# RS14100 register map
File version: 1.0
CPU: CM4 r0p1, little endian, MPU, FPU, 4 interrupt priority bits
Registers are 32-bit, read-write, reset 0x0 unless marked. A register's access mark holds for its fields unless they carry their own. Offsets are from the block's base; [hi:lo] are bit positions; {n}, {i} and the like mark numbered series; 'fields as' and 'values as' point back to an identical list.

## QSPI — The queued serial peripheral interface module provides a serial peripheral interface with queued transfer capability
Base 0x12000000
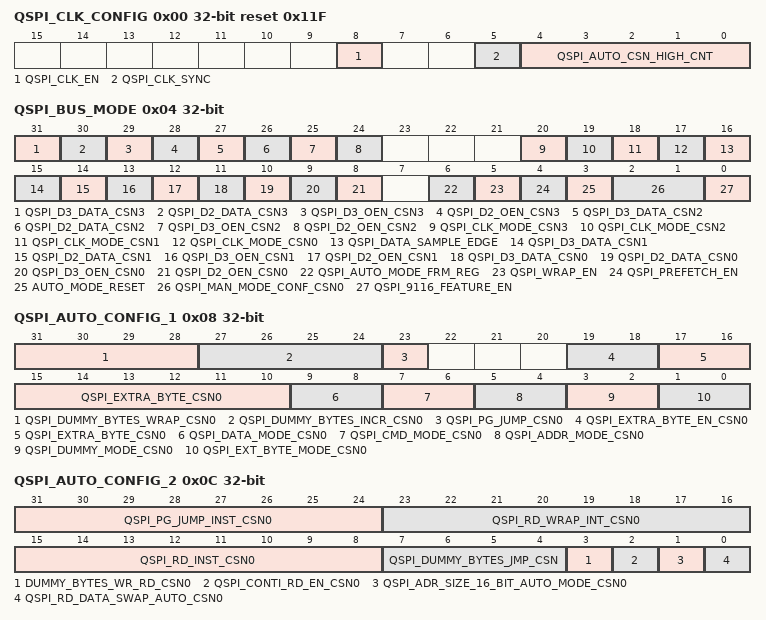
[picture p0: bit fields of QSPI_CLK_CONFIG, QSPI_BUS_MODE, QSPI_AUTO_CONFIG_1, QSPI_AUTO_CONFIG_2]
0x00 QSPI_CLK_CONFIG reset 0x11F — QSPI Clock Configuration Register
  [8] QSPI_CLK_EN — QSPI clock enable
    0=Disable (Dynamic clock gating is enabled in side QSPI controller); 1=Enable (Full time clock is enabled for QSPI controller.)
  [5] QSPI_CLK_SYNC — If the clock frequency to FLASH(spi_clk) and QSPI(hclk) controller is same, this bit can be set to one to by-pass the syncros results in time consumption
    0=Disable (Sync logic is enabled); 1=Enable (Sync (synchros) logic is bypassed)
  [4:0] QSPI_AUTO_CSN_HIGH_CNT — Minimum SOC clock cycles, during which QSPI auto csn should be high between consecutive CSN assertions
0x04 QSPI_BUS_MODE
  [31] QSPI_D3_DATA_CSN3 — Value of SPI_IO3 in case of dual/single mode for chip select3 csn3
  [30] QSPI_D2_DATA_CSN3 — Value of SPI_IO2 in case of dual/single mode for chip select3 csn3
  [29] QSPI_D3_OEN_CSN3 — Direction Control for SPI_IO3 in case of dual/single mode for chip select3 csn3
  [28] QSPI_D2_OEN_CSN3 — Direction Control for SPI_IO2 in case of dual/single mode for chip select3 csn3
  [27] QSPI_D3_DATA_CSN2 — Value of SPI_IO3 in case of dual/single mode for chip select2 csn2
  [26] QSPI_D2_DATA_CSN2 — Value of SPI_IO2 in case of dual/single mode for chip select2 csn2
  [25] QSPI_D3_OEN_CSN2 — Direction Control for SPI_IO3 in case of dual/single mode for chip select2 csn2
  [24] QSPI_D2_OEN_CSN2 — Direction Control for SPI_IO2 in case of dual/single mode for chip select2 csn2
  [20] QSPI_CLK_MODE_CSN3 — QSPI Clock Mode
    0=Mode 0, QSPI_CLK is low when QSPI_CS is high for chip select3 csn3; 1=Mode 3, QSPI_CLK is high when QSPI_CS is high for chip select3 csn3
  [19] QSPI_CLK_MODE_CSN2 — QSPI Clock Mode
    0=Mode 0 QSPI_CLK is low when QSPI_CS is high for chip select2 csn2; 1=Mode 3 QSPI_CLK is high when QSPI_CS is high for chip select2 csn2
  [18] QSPI_CLK_MODE_CSN1 — QSPI Clock Mode
    0=Mode 0, QSPI_CLK is low when QSPI_CS is high for chip select1 csn1; 1=Mode 3, QSPI_CLK is high when QSPI_CS is high for chip select1 csn1
  [17] QSPI_CLK_MODE_CSN0 — QSPI Clock Mode
    0=Mode 0, QSPI_CLK is low when QSPI_CS is high for chip select0 csn0; 1=Mode 3, QSPI_CLK is high when QSPI_CS is high for chip select0 csn0
  [16] QSPI_DATA_SAMPLE_EDGE — Samples MISO data on clock edges
    0=Disable (Pos edge of loop back spi_pad_clk); 1=Enable (Neg edge of loop back spi_pad_clk)
  [15] QSPI_D3_DATA_CSN1 — Value of SPI_IO3 in case of dual/single mode for chip select1 csn1
  [14] QSPI_D2_DATA_CSN1 — Direction Control for SPI_IO3 in case of dual/single mode for chip select1 csn1
  [13] QSPI_D3_OEN_CSN1 — Direction Control for SPI_IO3 in case of dual/single mode for chip select1 csn1
  [12] QSPI_D2_OEN_CSN1 — Direction Control for SPI_IO2 in case of dual/single mode for chip select1 csn1
  [11] QSPI_D3_DATA_CSN0 — Value of SPI_IO3 in case of dual/single mode for chip select0 csn0. It is used both in Auto and Manual Mode
  [10] QSPI_D2_DATA_CSN0 — Value of SPI_IO2 in case of dual/single mode for chip select0 csn0. It is used both in Auto and Manual Mode.
  [9] QSPI_D3_OEN_CSN0 — Direction Control for SPI_IO3 in case of dual/single mode for chip select0 csn0. It is used both in Auto and Manual Mode.
  [8] QSPI_D2_OEN_CSN0 — Direction Control for SPI_IO2 in case of dual/single mode for chip select0 csn0. It is used both in Auto and Manual Mode
  [6] QSPI_AUTO_MODE_FRM_REG — QSPI Mode of Operation
    0=Disable (Manual Mode is selected); 1=Enable (Auto Mode is selected.)
  [5] QSPI_WRAP_EN — Model wrap is considered with this bit and uses wrap instruction to read from FLASH
    0=Disable (Wrap mode is disabled (AHB WRAP can be used).); 1=Enable (Wrap mode is enabled)
  [4] QSPI_PREFETCH_EN — Pre-fetch of data from the model which is connected to QSPI, automatically with out reading on AHB and is supplied to AHB, when address is matched with AHB read transaction address
    0=Disable (Pre-fetch mode is disabled.); 1=Enable (Pre-fetch mode is enabled)
  [3] AUTO_MODE_RESET — QSPI Auto controller reset. This is not a Self clearing bit
    0=Disable (Auto mode is active); 1=Enable (Auto mode is inactive)
  [2:1] QSPI_MAN_MODE_CONF_CSN0 — Configures the QSPI flash for Single/Dual/Quad mode operation in manual mode
    0=Single Mode; 1=Dual Mode; 2=Quad Mode; 3=none
  [0] QSPI_9116_FEATURE_EN — 9115 specific features are enabled with this enable
0x08 QSPI_AUTO_CONFIG_1 — QSPI Auto Controller Configuration 1 Register
  [31:28] QSPI_DUMMY_BYTES_WRAP_CSN0 — Specifies the number of dummy bytes 0 to 7 for the selected SPI mode in case of wrap instruction
  [27:24] QSPI_DUMMY_BYTES_INCR_CSN0 — Specifies the number of dummy bytes 0 to 7 for the selected SPI mode
  [23] QSPI_PG_JUMP_CSN0
    0=NOT_INDEX_JUMP_INSTRUCTION (Do not use Index jump instruction); 1=INDEX_JUMP_INSTRUCTION (Use Index jump instruction specified by QSPI_PG_JUMP_INST)
  [19:18] QSPI_EXTRA_BYTE_EN_CSN0 — Value of the extra byte to be transmitted, if the extra byte mode is enabled
    0=Do not transmit extra byte; 1=Transmit Extra byte after address phase; 2=Transmit only first nibble of the byte and maintain Hi-Z on the IO bus for next nibble; 3=none
  [17:10] QSPI_EXTRA_BYTE_CSN0 — Value of the extra byte to be transmitted, if the extra byte mode is enabled
  [9:8] QSPI_DATA_MODE_CSN0 — Mode of operation of QSPI in DATA phase
    0=SPI; 1=Dual SPI; 2=Quad SPI; 3=none
  [7:6] QSPI_CMD_MODE_CSN0 — Mode of operation of QSPI in instruction phase
    0=SPI; 1=Dual SPI; 2=Quad SPI; 3=none
  [5:4] QSPI_ADDR_MODE_CSN0 — Mode of operation of QSPI in instruction phase
    0=SPI; 1=Dual SPI; 2=Quad SPI; 3=none
  [3:2] QSPI_DUMMY_MODE_CSN0 — Mode of operation of QSPI in instruction phase
    0=SPI; 1=Dual SPI; 2=Quad SPI; 3=none
  [1:0] QSPI_EXT_BYTE_MODE_CSN0 — Mode of operation of QSPI in the extra byte phase
    0=SPI; 1=Dual SPI; 2=Quad SPI; 3=none
0x0C QSPI_AUTO_CONFIG_2 — QSPI Auto Controller Configuration 2 Register
  [31:24] QSPI_PG_JUMP_INST_CSN0 — Read instruction to be used, when Page jump is to be used
  [23:16] QSPI_RD_WRAP_INT_CSN0 — Read instruction to be used, when wrap mode is supported by QSPI flash
  [15:8] QSPI_RD_INST_CSN0 — Read instruction to be used for the selected SPI modes and when wrap
  [7:4] QSPI_DUMMY_BYTES_JMP_CSN — Dummy cycles to be selected in case of JUMP
  [3] DUMMY_BYTES_WR_RD_CSN0 — Dummy bytes to the model to be read or to be write
    0=Disable (Dummy bytes will be read); 1=Enable (Dummy bytes to be write.)
  [2] QSPI_CONTI_RD_EN_CSN0
    0=Disable (Continuous read disabled.); 1=Enable (Continuous read enabled.)
  [1] QSPI_ADR_SIZE_16_BIT_AUTO_MODE_CSN0
    0=Disable (24 bit address is sent to model); 1=Enable (16 Bit address is sent to model)
  [0] QSPI_RD_DATA_SWAP_AUTO_CSN0
    0=Disable (Do not swap the read data in auto mode); 1=Enable (Swap the auto read data in auto mode)
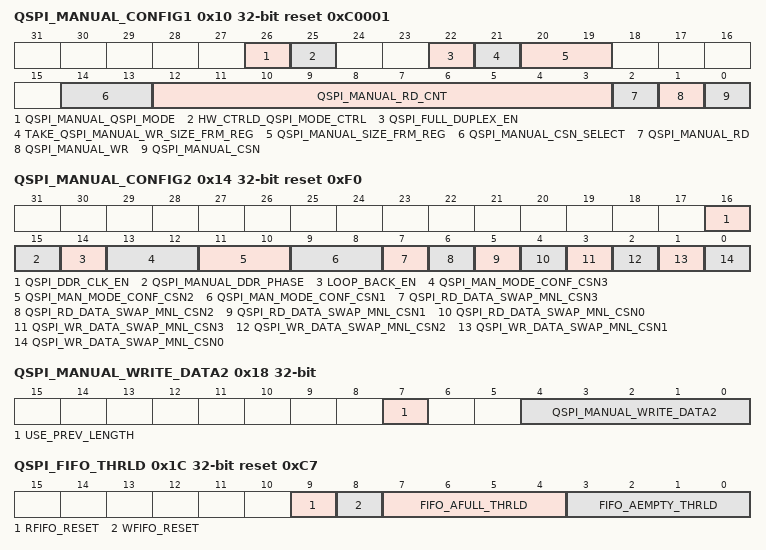
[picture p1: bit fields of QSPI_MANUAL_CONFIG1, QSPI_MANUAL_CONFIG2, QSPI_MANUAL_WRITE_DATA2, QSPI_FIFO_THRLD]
0x10 QSPI_MANUAL_CONFIG1 reset 0xC0001 — QSPI Manual Configuration 1 Register
  [26] QSPI_MANUAL_QSPI_MODE — Internally the priority is given to manual mode
    0=Disable (SPI mode); 1=Enable (Host SPI mode.)
  [25] HW_CTRLD_QSPI_MODE_CTRL — Hardware controlled qspi mode in between AUTO and manual
    0=Disable (Hardware control is disabled); 1=Enable (Hardware control is enabled.)
  [22] QSPI_FULL_DUPLEX_EN — Full duplex mode enable.
    0=Disable (Full duplex mode disabled.); 1=Enable (Full duplex mode enabled)
  [21] TAKE_QSPI_MANUAL_WR_SIZE_FRM_REG
    0=Disable (No action. Takes write size from fifo); 1=Enable (Take write size from Manual config register1)
  [20:19] QSPI_MANUAL_SIZE_FRM_REG — Manual reads and manual writes follow this size
    0=1BYTE_MODE (1 Byte 8 bit mode); 1=2BYTE_MODE (2 Bytes 16 bit mode); 2=3BYTE_MODE (3 Bytes 24 bit mode); 3=4BYTE_MODE (4 Bytes 32 bit mode)
  [14:13] QSPI_MANUAL_CSN_SELECT — Indicates which CSn is valid
  [12:3] QSPI_MANUAL_RD_CNT — Indicates total number of bytes to be read along with 31:27 bits of this register. Maximum length supported is 32k bytes
  [2] QSPI_MANUAL_RD — Read enable for manual mode when CS is low
  [1] QSPI_MANUAL_WR — Write enable for manual mode when CS is low
  [0] QSPI_MANUAL_CSN — SPI CS in manual mode
0x14 QSPI_MANUAL_CONFIG2 reset 0xF0 (reset mask 0xFFF) — QSPI Manual Configuration 2 Register
  [16] QSPI_DDR_CLK_EN — DDR operations can be performed even in manual mode
    0=Use SDR mode clk; 1=Use DDR mode clk
  [15] QSPI_MANUAL_DDR_PHASE — DDR operations can be performed even in manual mode
  [14] LOOP_BACK_EN — Internal loop back test mode.
  [13:12] QSPI_MAN_MODE_CONF_CSN3 — Configures the QSPI flash for Single or Dual or Quad mode operation in manual mode for chip select3 csn3
    0=Single; 1=Dual; 2=Quad; 3=none
  [11:10] QSPI_MAN_MODE_CONF_CSN2 — Configures the QSPI flash for Single or Dual or Quad mode operation in manual mode for chip select2 csn2
    0=Single; 1=Dual; 2=Quad; 3=none
  [9:8] QSPI_MAN_MODE_CONF_CSN1 — Configures the QSPI flash for Single/Dual/Quad mode operation in manual mode for chip select1 csn1
    0=Single; 1=Dual; 2=Quad; 3=none
  [7] QSPI_RD_DATA_SWAP_MNL_CSN3 — Swap the read data inside the QSPIcontroller itself
    0=Disable (Manual read data swap is disabled for csn3); 1=Enable (Manual read data swap is enabled for csn3)
  [6] QSPI_RD_DATA_SWAP_MNL_CSN2 — Swap the read data inside the QSPIcontroller it-self
    0=Disable (Manual read data swap is disabled for csn2); 1=Enable (Manual read data swap is enabled for csn2)
  [5] QSPI_RD_DATA_SWAP_MNL_CSN1 — Swap the read data inside the QSPIcontroller itself.
    0=Disable (Manual read data swap is disabled for csn1); 1=Enable (Manual read data swap is enabled for csn1)
  [4] QSPI_RD_DATA_SWAP_MNL_CSN0 — Swap the read data inside the QSPIcontroller it self.
    0=Disable (Manual read data swap is disabled for csn0.); 1=Enable (Manual read data swap is enabled for csn0.)
  [3] QSPI_WR_DATA_SWAP_MNL_CSN3 — Swap the write data inside the QSPI controller itself.
    0=Disable (Manual write data swap is disabled for csn3.); 1=Enable (Manual write data swap is enabled for csn3.)
  [2] QSPI_WR_DATA_SWAP_MNL_CSN2 — Swap the write data inside the QSPI controller itself.
    0=Disable (Manual write data swap is disabled for csn2.); 1=Enable (Manual write data swap is enabled for csn2.)
  [1] QSPI_WR_DATA_SWAP_MNL_CSN1 — Swap the write data inside the QSPI controller it-self.
    0=Disable (Manual write data swap is disabled for csn1.); 1=Enable (Manual write data swap is enabled for csn1.)
  [0] QSPI_WR_DATA_SWAP_MNL_CSN0 — Swap the write data inside the QSPI controller it-self
    0=Disable (Manual write data swap is disabled for csn0.); 1=Enable (Manual write data swap is enabled for csn0.)
0x18 QSPI_MANUAL_WRITE_DATA2
  [7] USE_PREV_LENGTH — Use previous length.
    0=Disable (No action); 1=Enable (Uses previously programmed length in 4:0 of this register for next writes)
  [4:0] QSPI_MANUAL_WRITE_DATA2 — Number of bits to be written in write mode
0x1C QSPI_FIFO_THRLD reset 0xC7 (reset mask 0x1FF) — QSPI FIFO Threshold Register
  [9] RFIFO_RESET — Read fifo reset
  [8] WFIFO_RESET — Write fifo reset
  [7:4] FIFO_AFULL_THRLD — FIFO almost full threshold
  [3:0] FIFO_AEMPTY_THRLD — FIFO almost empty threshold
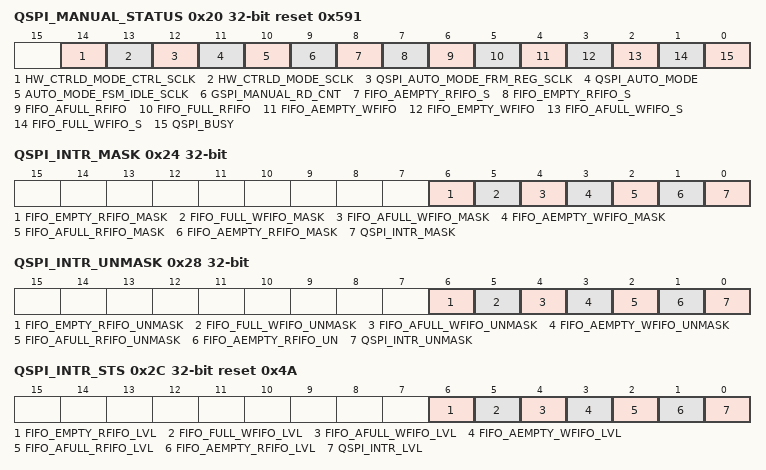
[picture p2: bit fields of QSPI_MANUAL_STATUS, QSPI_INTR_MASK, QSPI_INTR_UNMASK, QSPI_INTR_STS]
0x20 QSPI_MANUAL_STATUS ro reset 0x591
  [14] HW_CTRLD_MODE_CTRL_SCLK — HW_CTRLD_MODE status
    0=Disable (HW_CTRL_MODE is disabled.); 1=Enable (HW_CTRL_MODE is enabled)
  [13] HW_CTRLD_MODE_SCLK — QSPI mode status in HW_CTRLD_MODE
    0=Disable (QSPI controller is in MANUAL mode.); 1=Enable (QSPI controller is working in AUTO MODE.)
  [12] QSPI_AUTO_MODE_FRM_REG_SCLK — QSPI auto mode status. Valid only when HW_CTRLD_QSPI_MODE_CTRL is zero.
    0=Disable (QSPI controller is hot coded to manual mode operations.); 1=Enable (QSPI controller is hot coded to AUTO mode operations)
  [11] QSPI_AUTO_MODE — QSPI controller status.
    0=Disable (QSPI controller is in manual mode.); 1=Enable (QSPI controller is in auto mode.)
  [10] AUTO_MODE_FSM_IDLE_SCLK — Auto mode idle signal to track auto controller is busy or idle.
    0=Disable (Auto mode is busy); 1=Enable (Auto mode is idle)
  [9] GSPI_MANUAL_RD_CNT — This is a result of 10 bits ORing counter
    0=Disable (No read transactions are in pending); 1=Enable (Read transactions are in pending ( to be done))
  [8] FIFO_AEMPTY_RFIFO_S — Status indication for Rfifo in manual mode
  [7] FIFO_EMPTY_RFIFO_S — Status indication for Rfifo in manual mode
  [6] FIFO_AFULL_RFIFO — Status indication for Rfifo in manual mode
  [5] FIFO_FULL_RFIFO — Status indication for Rfifo in manual mode
  [4] FIFO_AEMPTY_WFIFO — Status indication for Wfifo in manual mode
  [3] FIFO_EMPTY_WFIFO — Status indication for Wfifo in manual mode
  [2] FIFO_AFULL_WFIFO_S — Status indication for Wfifo in manual mode
  [1] FIFO_FULL_WFIFO_S — Status indication for Wfifo in manual mode
  [0] QSPI_BUSY — State of Manual mode.
    0=Disable (QSPI controller is IDLE in Manual mode.); 1=Enable (A read, write or dummy cycle operation is in process in manual mode.)
0x24 QSPI_INTR_MASK (reset mask 0x6F) — QSPI Interrupt Mask Register
  [6] FIFO_EMPTY_RFIFO_MASK
    0=Disable (Do not touch); 1=Enable (Read fifo is empty intr mask)
  [5] FIFO_FULL_WFIFO_MASK
    0=Disable (Do not touch); 1=Enable (write fifo full intr mask)
  [4] FIFO_AFULL_WFIFO_MASK
    0=Disable (Do not touch); 1=Enable (Write fifo almost full intr mask)
  [3] FIFO_AEMPTY_WFIFO_MASK
    0=Disable (Do not touch); 1=Enable (write fifo almost empty intr mask.)
  [2] FIFO_AFULL_RFIFO_MASK
    0=Disable (Do not touch); 1=Enable (read fifo almost full intr mask)
  [1] FIFO_AEMPTY_RFIFO_MASK
    0=Disable (Do not touch); 1=Enable (Read fifo almost empty intr mask.)
  [0] QSPI_INTR_MASK — Interrupt Status bit
    0=Disable (Do not touch); 1=Enable (mask the qspi intr)
0x28 QSPI_INTR_UNMASK — QSPI Interrupt Unmask Register
  [6] FIFO_EMPTY_RFIFO_UNMASK
    0=Disable (Do not touch); 1=Enable (Read fifo is empty intr unmask)
  [5] FIFO_FULL_WFIFO_UNMASK
    0=Disable (Do not touch); 1=Enable (write fifo full intr unmask)
  [4] FIFO_AFULL_WFIFO_UNMASK
    0=Disable (Do not touch); 1=Enable (Write fifo almost full intr unmask.)
  [3] FIFO_AEMPTY_WFIFO_UNMASK
    0=Disable (Do not touch); 1=Enable (write fifo almost empty intr unmask)
  [2] FIFO_AFULL_RFIFO_UNMASK
    0=Disable (Do not touch); 1=Enable (read fifo almost full intr unmask.)
  [1] FIFO_AEMPTY_RFIFO_UN
    0=Disable (Do not touch); 1=Enable (Read fifo almost empty intr unmask)
  [0] QSPI_INTR_UNMASK — Interrupt Status bit
    0=Disable (Do not touch); 1=Enable (unmask the qspi intr)
0x2C QSPI_INTR_STS ro reset 0x4A — QSPI Interrupt Status Register
  [6] FIFO_EMPTY_RFIFO_LVL
    0=Disable (Read FIFO is not empty); 1=Enable (Read FIFO is empty)
  [5] FIFO_FULL_WFIFO_LVL
    0=Disable (Write fifo not got full); 1=Enable (write fifo got full.)
  [4] FIFO_AFULL_WFIFO_LVL
    0=Disable (write FIFO not reached almost full threshold); 1=Enable (Write FIFO reached almost full threshold)
  [3] FIFO_AEMPTY_WFIFO_LVL
    0=Disable (write FIFO not reached almost full threshold.); 1=Enable (write FIFO reached almost empty threshold.)
  [2] FIFO_AFULL_RFIFO_LVL
    0=Disable (read FIFO do not reached almost full threshold); 1=Enable (read FIFO reached almost full threshold)
  [1] FIFO_AEMPTY_RFIFO_LVL
    0=Disable (Read fifo does not reached almost empty threshold); 1=Enable (Read fifo reached almost empty threshold)
  [0] QSPI_INTR_LVL — Interrupt Status bit
    0=Disable (no interrupt); 1=Enable (qspi raised a interrupt)
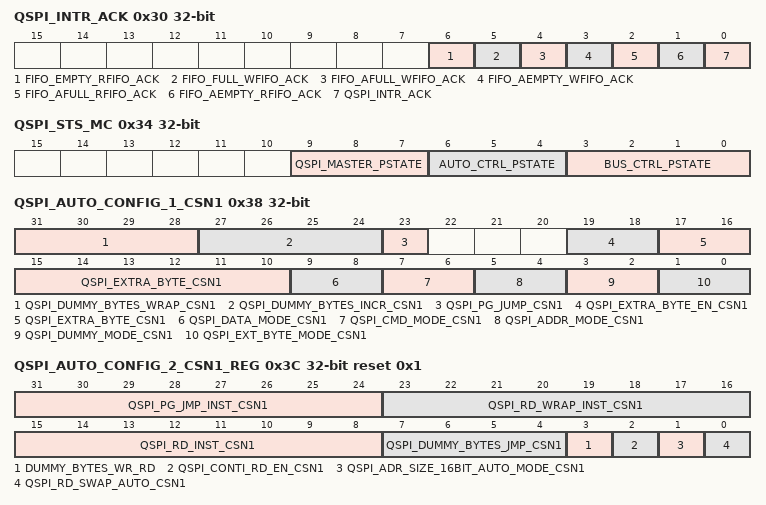
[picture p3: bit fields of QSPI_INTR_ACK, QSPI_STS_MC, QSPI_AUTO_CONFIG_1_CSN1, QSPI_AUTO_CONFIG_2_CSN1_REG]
0x30 QSPI_INTR_ACK wo — QSPI Interrupt Acknowledge Register
  [6] FIFO_EMPTY_RFIFO_ACK
    values as QSPI_INTR_UNMASK.FIFO_EMPTY_RFIFO_UNMASK
  [5] FIFO_FULL_WFIFO_ACK
    values as QSPI_INTR_UNMASK.FIFO_FULL_WFIFO_UNMASK
  [4] FIFO_AFULL_WFIFO_ACK
    values as QSPI_INTR_UNMASK.FIFO_AFULL_WFIFO_UNMASK
  [3] FIFO_AEMPTY_WFIFO_ACK
    0=Disable (Do not touch); 1=Enable (write fifo almost empty intr unmask.)
  [2] FIFO_AFULL_RFIFO_ACK
    values as QSPI_INTR_UNMASK.FIFO_AFULL_RFIFO_UNMASK
  [1] FIFO_AEMPTY_RFIFO_ACK
    values as QSPI_INTR_UNMASK.FIFO_AEMPTY_RFIFO_UN
  [0] QSPI_INTR_ACK — Interrupt Status bit
    0=Disable (Do not touch); 1=Enable (unmask the qspi intr.)
0x34 QSPI_STS_MC ro (reset mask 0x6FF) — QSPI State Machine Monitor Register
  [9:7] QSPI_MASTER_PSTATE — Qspi master present state
  [6:4] AUTO_CTRL_PSTATE — Auto controller present state
  [3:0] BUS_CTRL_PSTATE — Bus controller present state
0x38 QSPI_AUTO_CONFIG_1_CSN1 (reset mask 0x87FFFF) — QSPI Auto Controller Configuration 1 CSN1 Register
  [31:28] QSPI_DUMMY_BYTES_WRAP_CSN1 ro — Specifies the number of dummy bytes 0 to 7 for the selected SPI mode in case of wrap instruction.
  [27:24] QSPI_DUMMY_BYTES_INCR_CSN1 ro — Specifies the number of dummy bytes 0 to 7 for the selected SPI mode.
  [23] QSPI_PG_JUMP_CSN1 wo
    0=Disable (Do not use Index jump instruction.); 1=Enable (Use Index jump instruction specified by QSPI_PG_JUMP_INST)
  [19:18] QSPI_EXTRA_BYTE_EN_CSN1 — Mode of operation of QSPI in DATA phase.
    values as QSPI_AUTO_CONFIG_1.QSPI_EXTRA_BYTE_EN_CSN0
  [17:10] QSPI_EXTRA_BYTE_CSN1 ro — Value of the extra byte to be transmitted, if the extra byte mode is enabled.
  [9:8] QSPI_DATA_MODE_CSN1 — Mode of operation of QSPI in DATA phase.
    0=SPI; 1=Dual SPI; 2=Quad SPI; 3=none
  [7:6] QSPI_CMD_MODE_CSN1 — Mode of operation of QSPI in instruction phase.
    0=SPI; 1=Dual SPI; 2=Quad SPI; 3=none
  [5:4] QSPI_ADDR_MODE_CSN1 — Mode of operation of QSPI in instruction phase.
    0=SPI; 1=Dual SPI; 2=Quad SPI; 3=none
  [3:2] QSPI_DUMMY_MODE_CSN1 — Mode of operation of QSPI in instruction phase
    0=SPI; 1=Dual SPI; 2=Quad SPI; 3=none
  [1:0] QSPI_EXT_BYTE_MODE_CSN1 — Mode of operation of QSPI in instruction phase.
    0=SPI; 1=Dual SPI; 2=Quad SPI; 3=none
0x3C QSPI_AUTO_CONFIG_2_CSN1_REG reset 0x1 — QSPI Auto Controller Configuration 2 CSN1 Register
  [31:24] QSPI_PG_JMP_INST_CSN1 — Read instruction to be used, when Page jump is to be used.
  [23:16] QSPI_RD_WRAP_INST_CSN1 — Read instruction to be used for the selected SPI modes and when wrap is not needed or supported
  [15:8] QSPI_RD_INST_CSN1 — Read instruction to be used for the selected SPI modes and when wrap is not needed or supported
  [7:4] QSPI_DUMMY_BYTES_JMP_CSN1 — Dummy cycles to be selected in case of JUMP
  [3] DUMMY_BYTES_WR_RD — Dummy bytes to the model to be read or to be write.
    0=READ (Dummy bytes will be read.); 1=WRITE (Dummy bytes to be write.)
  [2] QSPI_CONTI_RD_EN_CSN1 — Continuous read enable bit.
    0=disable (Continuous read disabled); 1=enable (Continuous read enabled)
  [1] QSPI_ADR_SIZE_16BIT_AUTO_MODE_CSN1
    0=24BIT_ADDRESS (24 bit address is sent to model); 1=16BIT_ADDRESS (16 Bit address is sent to model.)
  [0] QSPI_RD_SWAP_AUTO_CSN1 — Swap the read data from the flash in byte order for chip select1 csn1 in auto mode.
    0=Swap is disabled; 1=Swap is enabled
{0x40+4i} QSPI_MANUAL_RDWR_FIFO[{i}] (i=0..15) — QSPI FIFOs
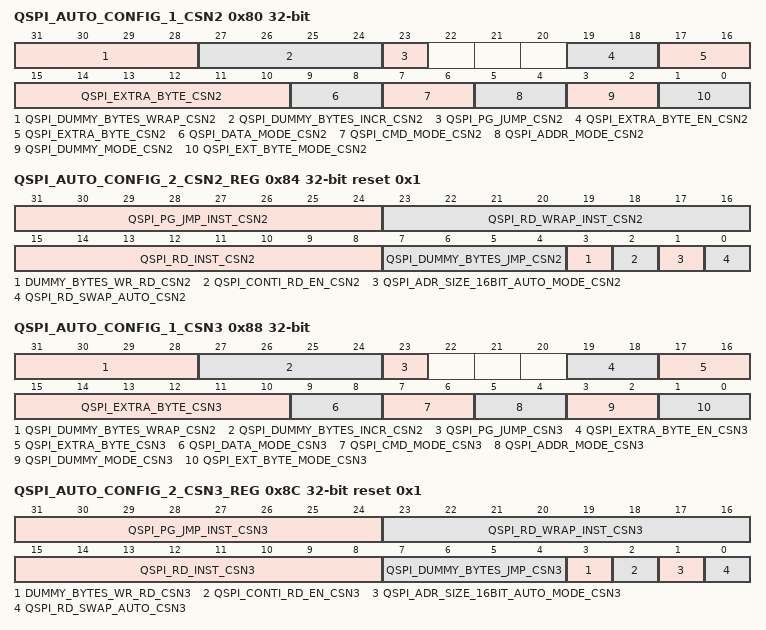
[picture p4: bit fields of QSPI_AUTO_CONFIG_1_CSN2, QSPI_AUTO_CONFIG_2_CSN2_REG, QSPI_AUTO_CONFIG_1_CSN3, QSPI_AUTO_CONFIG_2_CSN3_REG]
0x80 QSPI_AUTO_CONFIG_1_CSN2 (reset mask 0x87FFFF) — QSPI Auto Controller Configuration 1 CSN2 Register
  [31:28] QSPI_DUMMY_BYTES_WRAP_CSN2 ro — Specifies the number of dummy bytes 0 to 7 for the selected SPI mode in case of wrap instruction.
  [27:24] QSPI_DUMMY_BYTES_INCR_CSN2 ro — Specifies the number of dummy bytes 0 to 7 for the selected SPI mode.
  [23] QSPI_PG_JUMP_CSN2 wo
    values as QSPI_AUTO_CONFIG_1_CSN1.QSPI_PG_JUMP_CSN1
  [19:18] QSPI_EXTRA_BYTE_EN_CSN2 — Mode of operation of QSPI in DATA phase.
    values as QSPI_AUTO_CONFIG_1.QSPI_EXTRA_BYTE_EN_CSN0
  [17:10] QSPI_EXTRA_BYTE_CSN2 ro — Value of the extra byte to be transmitted, if the extra byte mode is enabled.
  [9:8] QSPI_DATA_MODE_CSN2 — Mode of operation of QSPI in DATA phase.
    0=SPI; 1=Dual SPI; 2=Quad SPI; 3=none
  [7:6] QSPI_CMD_MODE_CSN2 — Mode of operation of QSPI in instruction phase.
    0=SPI; 1=Dual SPI; 2=Quad SPI; 3=none
  [5:4] QSPI_ADDR_MODE_CSN2 — Mode of operation of QSPI in instruction phase.
    0=SPI; 1=Dual SPI; 2=Quad SPI; 3=none
  [3:2] QSPI_DUMMY_MODE_CSN2 — Mode of operation of QSPI in instruction phase
    0=SPI; 1=Dual SPI; 2=Quad SPI; 3=none
  [1:0] QSPI_EXT_BYTE_MODE_CSN2 — Mode of operation of QSPI in instruction phase.
    0=SPI; 1=Dual SPI; 2=Quad SPI; 3=none
0x84 QSPI_AUTO_CONFIG_2_CSN2_REG reset 0x1 — QSPI Auto Controller Configuration 2 CSN2 Register
  [31:24] QSPI_PG_JMP_INST_CSN2 — Read instruction to be used, when Page jump is to be used.
  [23:16] QSPI_RD_WRAP_INST_CSN2 — Read instruction to be used for the selected SPI modes and when wrap is not needed or supported
  [15:8] QSPI_RD_INST_CSN2 — Read instruction to be used for the selected SPI modes and when wrap is not needed or supported
  [7:4] QSPI_DUMMY_BYTES_JMP_CSN2 — Dummy cycles to be selected in case of JUMP
  [3] DUMMY_BYTES_WR_RD_CSN2 — Dummy bytes to the model to be read or to be write.
    0=Dummy bytes will be read; 1=Dummy bytes to be write
  [2] QSPI_CONTI_RD_EN_CSN2 — Continuous read enable bit.
    0=Continuous read disabled; 1=Continuous read enabled
  [1] QSPI_ADR_SIZE_16BIT_AUTO_MODE_CSN2
    0=24 bit address is sent to model; 1=16 Bit address is sent to model
  [0] QSPI_RD_SWAP_AUTO_CSN2 — Swap the read data from the flash in byte order for chip select1 csn1 in auto mode.
    0=Swap is disabled; 1=Swap is enabled
0x88 QSPI_AUTO_CONFIG_1_CSN3 (reset mask 0x87FFFF) — QSPI Auto Controller Configuration 1 CSN3 Register
  [31:28] QSPI_DUMMY_BYTES_WRAP_CSN2 ro — Specifies the number of dummy bytes 0 to 7 for the selected SPI mode in case of wrap instruction.
  [27:24] QSPI_DUMMY_BYTES_INCR_CSN2 ro — Specifies the number of dummy bytes 0 to 7 for the selected SPI mode.
  [23] QSPI_PG_JUMP_CSN3 wo
    values as QSPI_AUTO_CONFIG_1_CSN1.QSPI_PG_JUMP_CSN1
  [19:18] QSPI_EXTRA_BYTE_EN_CSN3 — Mode of operation of QSPI in DATA phase.
    values as QSPI_AUTO_CONFIG_1.QSPI_EXTRA_BYTE_EN_CSN0
  [17:10] QSPI_EXTRA_BYTE_CSN3 ro — Value of the extra byte to be transmitted, if the extra byte mode is enabled.
  [9:8] QSPI_DATA_MODE_CSN3 — Mode of operation of QSPI in DATA phase.
    0=SPI; 1=Dual SPI; 2=Quad SPI; 3=none
  [7:6] QSPI_CMD_MODE_CSN3 — Mode of operation of QSPI in instruction phase.
    0=SPI; 1=Dual SPI; 2=Quad SPI; 3=none
  [5:4] QSPI_ADDR_MODE_CSN3 — Mode of operation of QSPI in instruction phase.
    0=SPI; 1=Dual SPI; 2=Quad SPI; 3=none
  [3:2] QSPI_DUMMY_MODE_CSN3 — Mode of operation of QSPI in instruction phase
    0=SPI; 1=Dual SPI; 2=Quad SPI; 3=none
  [1:0] QSPI_EXT_BYTE_MODE_CSN3 — Mode of operation of QSPI in instruction phase.
    0=SPI; 1=Dual SPI; 2=Quad SPI; 3=none
0x8C QSPI_AUTO_CONFIG_2_CSN3_REG reset 0x1 — QSPI Auto Controller Configuration 2 CSN3 Register
  [31:24] QSPI_PG_JMP_INST_CSN3 — Read instruction to be used, when Page jump is to be used.
  [23:16] QSPI_RD_WRAP_INST_CSN3 — Read instruction to be used for the selected SPI modes and when wrap is not needed or supported
  [15:8] QSPI_RD_INST_CSN3 — Read instruction to be used for the selected SPI modes and when wrap is not needed or supported
  [7:4] QSPI_DUMMY_BYTES_JMP_CSN3 — Dummy cycles to be selected in case of JUMP
  [3] DUMMY_BYTES_WR_RD_CSN3 — Dummy bytes to the model to be read or to be write.
    0=Dummy bytes will be read; 1=Dummy bytes to be write
  [2] QSPI_CONTI_RD_EN_CSN3 — Continuous read enable bit.
    0=Continuous read disabled; 1=Continuous read enabled
  [1] QSPI_ADR_SIZE_16BIT_AUTO_MODE_CSN3
    values as QSPI_AUTO_CONFIG_2_CSN2_REG.QSPI_ADR_SIZE_16BIT_AUTO_MODE_CSN2
  [0] QSPI_RD_SWAP_AUTO_CSN3 — Swap the read data from the flash in byte order for chip select1 csn1 in auto mode.
    0=Swap is disabled; 1=Swap is enabled
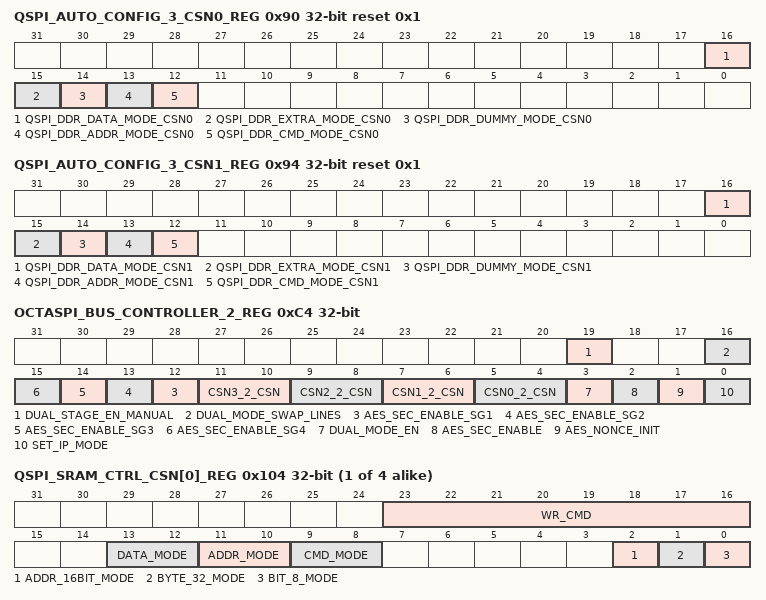
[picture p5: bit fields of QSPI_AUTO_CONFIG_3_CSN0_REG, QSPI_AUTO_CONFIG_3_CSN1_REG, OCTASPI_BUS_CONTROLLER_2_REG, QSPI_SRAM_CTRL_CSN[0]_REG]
0x90 QSPI_AUTO_CONFIG_3_CSN0_REG reset 0x1 — QSPI Auto Controller Configuration 3 CSN0 Register
  [16] QSPI_DDR_DATA_MODE_CSN0 — DDR Address mode
    0=Data are sampled in SDR fashion; 1=Data are sampled in DDR fashion
  [15] QSPI_DDR_EXTRA_MODE_CSN0 — DDR Address mode
    0=Extra byte is driven in SDR fashion; 1=Extra byte is driven in DDR fashion
  [14] QSPI_DDR_DUMMY_MODE_CSN0 — DDR Address mode
    0=Dummy bytes are driven in SDR fashion; 1=Dummy bytes are driven in DDR fashion
  [13] QSPI_DDR_ADDR_MODE_CSN0 — DDR Address mode
    0=Address bytes are driven in SDR fashion; 1=Address bytes are driven in DDR fashion
  [12] QSPI_DDR_CMD_MODE_CSN0 — DDR Command mode
    0=Command byte is driven in SDR fashion; 1=Command byte is driven in DDR fashion
0x94 QSPI_AUTO_CONFIG_3_CSN1_REG reset 0x1 — QSPI Auto Controller Configuration 3 CSN1 Register
  [16] QSPI_DDR_DATA_MODE_CSN1 — DDR Address mode
    values as QSPI_AUTO_CONFIG_3_CSN0_REG.QSPI_DDR_DATA_MODE_CSN0
  [15] QSPI_DDR_EXTRA_MODE_CSN1 — DDR Address mode
    values as QSPI_AUTO_CONFIG_3_CSN0_REG.QSPI_DDR_EXTRA_MODE_CSN0
  [14] QSPI_DDR_DUMMY_MODE_CSN1 — DDR Address mode
    values as QSPI_AUTO_CONFIG_3_CSN0_REG.QSPI_DDR_DUMMY_MODE_CSN0
  [13] QSPI_DDR_ADDR_MODE_CSN1 — DDR Address mode
    values as QSPI_AUTO_CONFIG_3_CSN0_REG.QSPI_DDR_ADDR_MODE_CSN0
  [12] QSPI_DDR_CMD_MODE_CSN1 — DDR Command mode
    values as QSPI_AUTO_CONFIG_3_CSN0_REG.QSPI_DDR_CMD_MODE_CSN0
0xC4 OCTASPI_BUS_CONTROLLER_2_REG
  [19] DUAL_STAGE_EN_MANUAL — Dual stage en for dual flash mode
  [16] DUAL_MODE_SWAP_LINES — This bit controls the 8 lines of qspi with 4 bit swap manner
  [n+11] AES_SEC_ENABLE_SG{n} (n=1..4) — This bit enables the AES security enable or not for segment {n}
  [11:10] CSN3_2_CSN — Map csn3 to the programmed csn. It is valid for both manual and auto modes
    0=Map csn3 to csn0. Reads on csn3 will have data from csn0 also.; 1=Map csn3 to csn1. Reads on csn3 will have data from csn0 also; 2=Map csn3 to csn2. Reads on csn3 will have data from csn0 also.; 3=Not valid
  [9:8] CSN2_2_CSN — Map csn2 to the programmed csn. It is valid for both manual and auto modes
    0=Map csn2 to csn1. Reads on csn2 will have data from csn0 also; 1=Map csn2 to csn1. Reads on csn2 will have data from csn1 also; 2=Not valid; 3=Map csn2 to csn3. Reads on csn2 will have data from csn3 also.
  [7:6] CSN1_2_CSN — Map csn1 to the programmed csn. It is valid for both manual and auto modes
    0=Map csn1 to csn0. Reads on csn1 will have data from csn1 also; 1=Not valid; 2=Map csn1 to csn2. Reads on csn1 will have data from csn2 also; 3=Map csn1 to csn3. Reads on csn1 will have data from csn3 also
  [5:4] CSN0_2_CSN — Map csn0 to the programmed csn. It is valid for both manual and auto modes
    0=Not valid; 1=Map csn0 to csn1. Reads on csn0 will have data from csn1 also; 2=Map csn0 to csn2. Reads on csn0 will have data from csn2 also; 3=Map csn0 to csn3. Reads on csn0 will have data from csn3 also
  [3] DUAL_MODE_EN — Dual flash mode enable control.
  [2] AES_SEC_ENABLE — This bit enables the AES security enable or not
  [1] AES_NONCE_INIT — This bit enables the AES initialization with nonce
  [0] SET_IP_MODE — This bit enables the qspi interface pins into HiZ mode
{0x104+4i} QSPI_SRAM_CTRL_CSN[{i}]_REG (i=0..3)
  [23:16] WR_CMD — Command to be used for writing
  [13:12] DATA_MODE — writing address mode
    0=Single SPI; 1=Dual SPI; 2=Quad SPI; 3=OCTA SPI
  [11:10] ADDR_MODE — writing address mode
    0=Single SPI; 1=Dual SPI; 2=Quad SPI; 3=OCTA SPI
  [9:8] CMD_MODE — writing cmd mode
    0=Single SPI; 1=Dual SPI; 2=Quad SPI; 3=OCTA SPI
  [2] ADDR_16BIT_MODE — Send only lower 16bits of Address enable.
    0=24 address bit flash is connected; 1=16 address bit flash is connected
  [1] BYTE_32_MODE — Flash 32 byte boundary mode
    0=Flash is not with 32 byte boundary; 1=Flash is with 32 byte boundary
  [0] BIT_8_MODE — Flash 8bit (1 byte) boundary mode
    0=Flash is not with 8bit (1 byte) boundary; 1=Flash is with 8bit (1 byte) boundary
0x11C SEMI_AUTO_MODE_ADDR_REG — Byte address to read the data from flash in semi auto mode. It is valid only semi auto mode enable bit is asserted
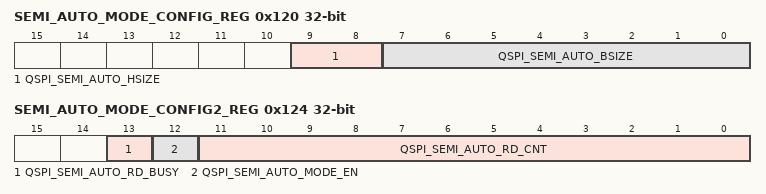
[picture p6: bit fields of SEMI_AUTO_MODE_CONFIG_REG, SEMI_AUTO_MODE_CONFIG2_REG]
0x120 SEMI_AUTO_MODE_CONFIG_REG
  [9:8] QSPI_SEMI_AUTO_HSIZE — Indicates number of bytes valid in each transaction
    0=1 byte valid; 1=2 bytes valid; 2=4 bytes valid; 3=none
  [7:0] QSPI_SEMI_AUTO_BSIZE — This is burst size to read data from flash in semi auto mode
0x124 SEMI_AUTO_MODE_CONFIG2_REG
  [13] QSPI_SEMI_AUTO_RD_BUSY — Indicates status of semi auto mode read status. If it is high, semi auto mode read operation is progressing
  [12] QSPI_SEMI_AUTO_MODE_EN — Enable for semi auto mode read operation. Make sure manual mode read/write operation is completed before asserting this bit
  [11:0] QSPI_SEMI_AUTO_RD_CNT — Total number of bytes to be read flash continuously from the address given by SEMI_AUTO_MODE_ADDR_REG
